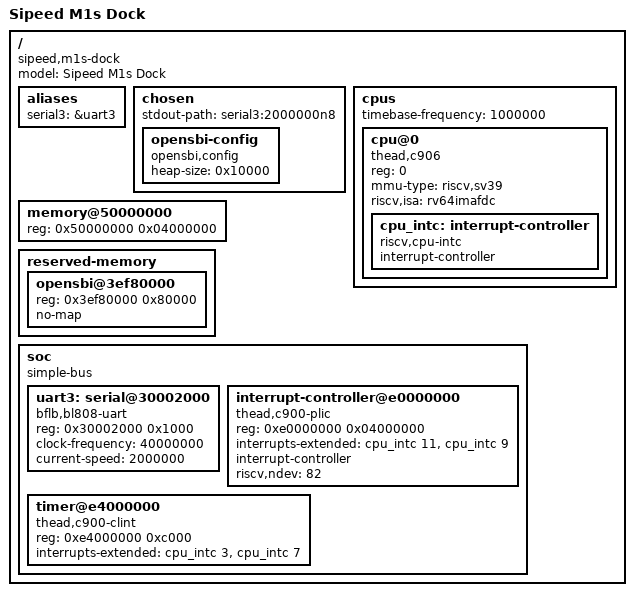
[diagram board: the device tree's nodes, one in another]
// SPDX-License-Identifier: BSD-2-Clause

/dts-v1/;

/ {
	compatible = "sipeed,m1s-dock", "bflb,bl808";
	model = "Sipeed M1s Dock";
	#address-cells = <1>;
	#size-cells = <1>;

	aliases {
		serial3 = &uart3;
	};

	chosen {
		stdout-path = "serial3:2000000n8";

		opensbi-config {
			compatible = "opensbi,config";
			heap-size = <0x10000>;
		};
	};

	cpus {
		timebase-frequency = <1000000>;
		#address-cells = <1>;
		#size-cells = <0>;

		cpu@0 {
			compatible = "thead,c906", "riscv";
			device_type = "cpu";
			reg = <0>;
			mmu-type = "riscv,sv39";
			riscv,isa = "rv64imafdc";

			cpu_intc: interrupt-controller {
				compatible = "riscv,cpu-intc";
				interrupt-controller;
				#address-cells = <0>;
				#interrupt-cells = <1>;
			};
		};
	};

	memory@50000000 {
		device_type = "memory";
		reg = <0x50000000 0x04000000>;
	};

	reserved-memory {
		#address-cells = <1>;
		#size-cells = <1>;
		ranges;

		opensbi@3ef80000 {
			reg = <0x3ef80000 0x80000>;
			no-map;
		};
	};

	soc {
		compatible = "simple-bus";
		#address-cells = <1>;
		#size-cells = <1>;
		ranges;

		uart3: serial@30002000 {
			compatible = "bflb,bl808-uart";
			reg = <0x30002000 0x1000>;
			clock-frequency = <40000000>;
			current-speed = <2000000>;
		};

		interrupt-controller@e0000000 {
			compatible = "thead,c900-plic";
			reg = <0xe0000000 0x04000000>;
			interrupts-extended = <&cpu_intc 11>, <&cpu_intc 9>;
			interrupt-controller;
			#address-cells = <0>;
			#interrupt-cells = <1>;
			riscv,ndev = <82>;
		};

		timer@e4000000 {
			compatible = "thead,c900-clint";
			reg = <0xe4000000 0xc000>;
			interrupts-extended = <&cpu_intc 3>, <&cpu_intc 7>;
		};
	};
};
